# DDRSS0_PHY_CFG register map
Vendor: Texas Instruments
Peripheral module from a debugger description file (folder am65x).
Registers are 32-bit, access per field, reset 0x0 unless marked. A register's access mark holds for its fields unless they carry their own. Offsets are as the file gives them; lines under a group give offsets from that group; [hi:lo] are bit positions; {n}, {i} and the like mark numbered series; 'fields as' and 'values as' point back to an identical list; <NAME> marks a mode.

## DDRSS0_PHY_CFG (part 1 of 2)
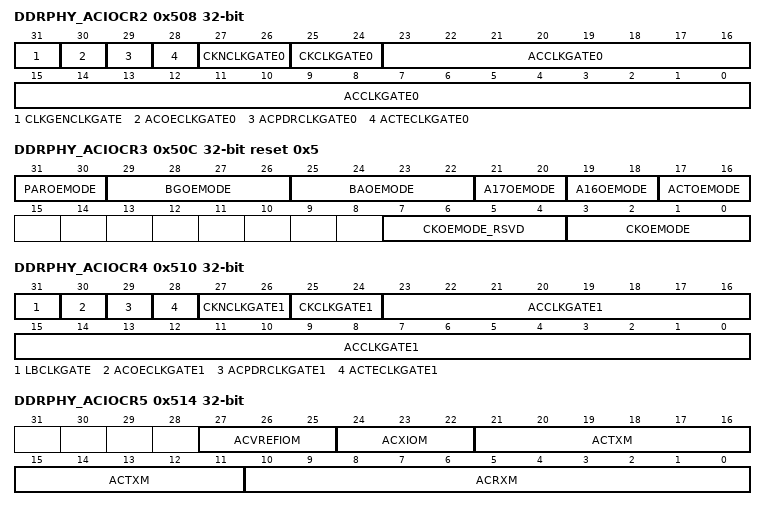
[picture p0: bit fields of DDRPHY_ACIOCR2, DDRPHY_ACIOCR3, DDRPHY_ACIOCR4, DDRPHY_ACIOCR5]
0x508 DDRPHY_ACIOCR2 rw — AC I/O Configuration Register 2
  [31] CLKGENCLKGATE — Clock gating for glue logic inside CLKGEN and glue logic inside CONTROL slice
  [30] ACOECLKGATE0 — Clock gating for Output Enable D slices [0]
  [29] ACPDRCLKGATE0 — Clock gating for Power Down Receiver D slices [0]
  [28] ACTECLKGATE0 — Clock gating for Termination Enable D slices [0]
  [27:26] CKNCLKGATE0 — Clock gating for CK# D slices[1:0]
  [25:24] CKCLKGATE0 — Clock gating for CK D slices[1:0]
  [23:0] ACCLKGATE0 — Clock gating for AC D slices[23:0]
0x50C DDRPHY_ACIOCR3 reset 0x5 — AC I/O Configuration Register 3
  [31:30] PAROEMODE rw — SDRAM Parity Output Enable (OE) Mode Selection
  [29:26] BGOEMODE rw — SDRAM Bank Group Output Enable (OE) Mode Selection
  [25:22] BAOEMODE rw — SDRAM Bank Address Output Enable (OE) Mode Selection
  [21:20] A17OEMODE rw — SDRAM A[17] Output Enable (OE) Mode Selection
  [19:18] A16OEMODE rw — SDRAM A[16] / RAS_n Output Enable (OE) Mode Selection
  [17:16] ACTOEMODE rw — SDRAM ACT_n Output Enable (OE) Mode Selection (DDR4 only)
  [7:4] CKOEMODE_RSVD ro — Reserved.Return zeros on reads.
  [3:0] CKOEMODE rw — SDRAM CK Output Enable (OE) Mode Selection.
0x510 DDRPHY_ACIOCR4 rw — AC I/O Configuration Register 4
  [31] LBCLKGATE — Clock gating for AC LB slices and loopback read valid slices
  [30] ACOECLKGATE1 — Clock gating for Output Enable D slices [1]
  [29] ACPDRCLKGATE1 — Clock gating for Power Down Receiver D slices [1]
  [28] ACTECLKGATE1 — Clock gating for Termination Enable D slices [1]
  [27:26] CKNCLKGATE1 — Clock gating for CK# D slices[3:2]
  [25:24] CKCLKGATE1 — Clock gating for CK D slices[3:2]
  [23:0] ACCLKGATE1 — Clock gating for AC D slices[47:24]
0x514 DDRPHY_ACIOCR5 — AC I/O Configuration Register 5
  [27:25] ACVREFIOM rw — IOM bits for PVREF and PVREFE cells in AC IO ring
  [24:22] ACXIOM rw — AC IO Mode
  [21:11] ACTXM rw — AC IO Transmitter Mode
  [10:0] ACRXM rw — AC IO Receiver Mode
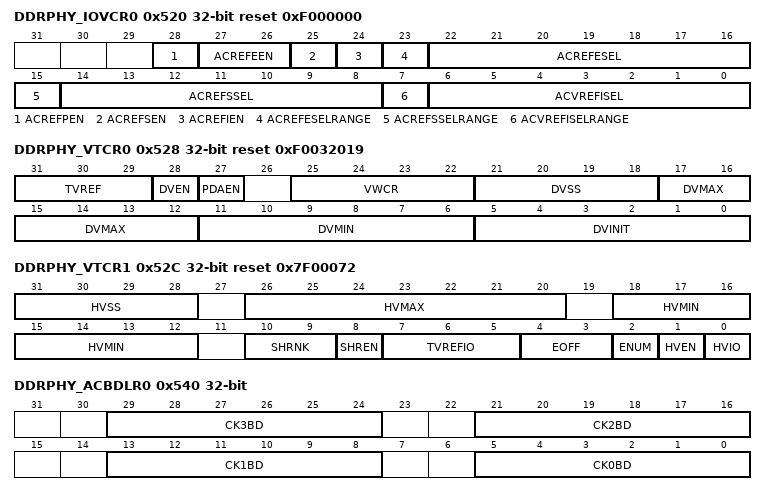
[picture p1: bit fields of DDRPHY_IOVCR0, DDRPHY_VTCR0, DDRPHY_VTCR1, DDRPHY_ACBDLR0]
0x520 DDRPHY_IOVCR0 reset 0xF000000 — IO VREF Control Register 0
  [28] ACREFPEN rw — Address/command lane VREF Pad Enable
  [27:26] ACREFEEN rw — Address/command lane Internal VREF Enable
  [25] ACREFSEN rw — Address/command lane Single-End VREF Enable
  [24] ACREFIEN rw — Address/command lane Internal VREF Enable
  [23] ACREFESELRANGE rw — External VREF generato REFSEL range select
  [22:16] ACREFESEL rw — Address/command lane External VREF Select
  [15] ACREFSSELRANGE rw — Single ended VREF generator REFSEL range select
  [14:8] ACREFSSEL rw — Address/command lane Single-End VREF Select
  [7] ACVREFISELRANGE rw — Internal VREF generator REFSEL ragne select
  [6:0] ACVREFISEL rw — REFSEL Control for internal AC IOs
0x528 DDRPHY_VTCR0 reset 0xF0032019 — VREF Training Control Register 0
  [31:29] TVREF rw — Number of ctl_clk required to meet (&gt; 150ns) timing requirements during DRAM DQ VREF training
  [28] DVEN rw — DRAM DQ VREF training Enable
  [27] PDAEN rw — Per Device Addressability Enable
  [25:22] VWCR rw — VREF Word Count
  [21:18] DVSS rw — DRAM DQ VREF step size used during DRAM VREF training
  [17:12] DVMAX rw — Maximum VREF limit value used during DRAM VREF training
  [11:6] DVMIN rw — Minimum VREF limit value used during DRAM VREF training
  [5:0] DVINIT rw — Initial DRAM DQ VREF value used during DRAM VREF training
0x52C DDRPHY_VTCR1 reset 0x7F00072 — VREF Training Control Register 1
  [31:28] HVSS rw — Host VREF step size used during VREF training.The register value of N indicates step size of (N+1)
  [26:20] HVMAX rw — Maximum VREF limit value used during DRAM VREF training.
  [18:12] HVMIN rw — Minimum VREF limit value used during DRAM VREF training.
  [10:9] SHRNK rw — Static Host Vref Rank Value
  [8] SHREN rw — Static Host Vref Rank Enable
  [7:5] TVREFIO rw — Number of ctl_clk required to meet (&gt; 200ns) VREF Settling timing requirements during Host IO VREF training
  [4:3] EOFF rw — Eye LCDL Offset value for VREF training
  [2] ENUM rw — Number of LCDL Eye points for which VREF training is repeated
  [1] HVEN rw — HOST (IO) internal VREF training Enable
  [0] HVIO rw — Host IO Type Control
0x540 DDRPHY_ACBDLR0 — AC Bit Delay Line Register 0
  [8n+5:8n] CK{n}BD rw (n=0..3) — CK{n} Bit Delay
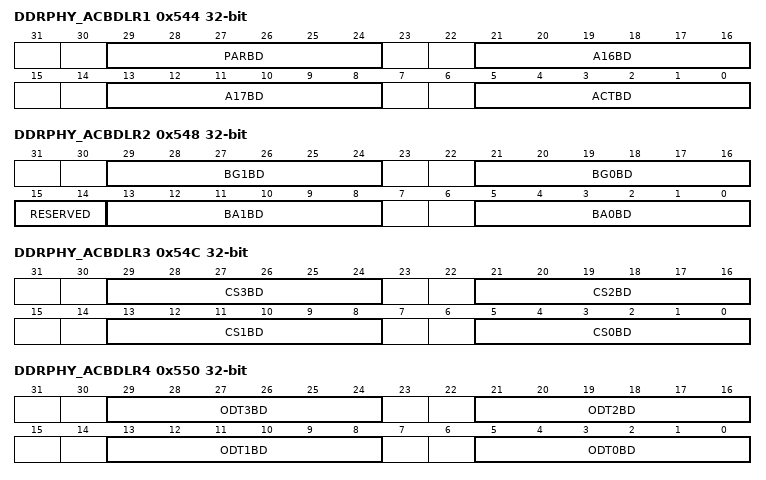
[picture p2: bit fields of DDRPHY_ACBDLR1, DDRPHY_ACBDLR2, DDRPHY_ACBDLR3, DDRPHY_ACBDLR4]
0x544 DDRPHY_ACBDLR1 — AC Bit Delay Line Register 1
  [29:24] PARBD rw — Delay select for the BDL on Parity.
  [21:16] A16BD rw — Delay select for the BDL on Address A[16].In DDR3 mode this pin is connected to WE.
  [13:8] A17BD rw — Delay select for the BDL on Address A[17].When not in DDR4 modemode this pin is connected to CAS.
  [5:0] ACTBD rw — Delay select for the BDL on ACTN.
0x548 DDRPHY_ACBDLR2 — AC Bit Delay Line Register 2
  [29:24] BG1BD rw — Delay select for the BDL on BG[1].
  [21:16] BG0BD rw — Delay select for the BDL on BG[0].
  [15:14] RESERVED ro — Reser.ved Return zeroes on reads.
  [13:8] BA1BD rw — Delay select for the BDL on BA[1].
  [5:0] BA0BD rw — Delay select for the BDL on BA[0].
0x54C DDRPHY_ACBDLR3 — AC Bit Delay Line Register 3
  [29:24] CS3BD ro — Delay select for the BDL on CS[3].
  [21:16] CS2BD ro — Delay select for the BDL on CS[2].
  [13:8] CS1BD rw — Delay select for the BDL on CS[1].
  [5:0] CS0BD rw — Delay select for the BDL on CS[0].
0x550 DDRPHY_ACBDLR4 — AC Bit Delay Line Register 4
  [29:24] ODT3BD ro — Delay select for the BDL on ODT[3].
  [21:16] ODT2BD ro — Delay select for the BDL on ODT[2].
  [13:8] ODT1BD rw — Delay select for the BDL on ODT[1].
  [5:0] ODT0BD rw — Delay select for the BDL on ODT[0].
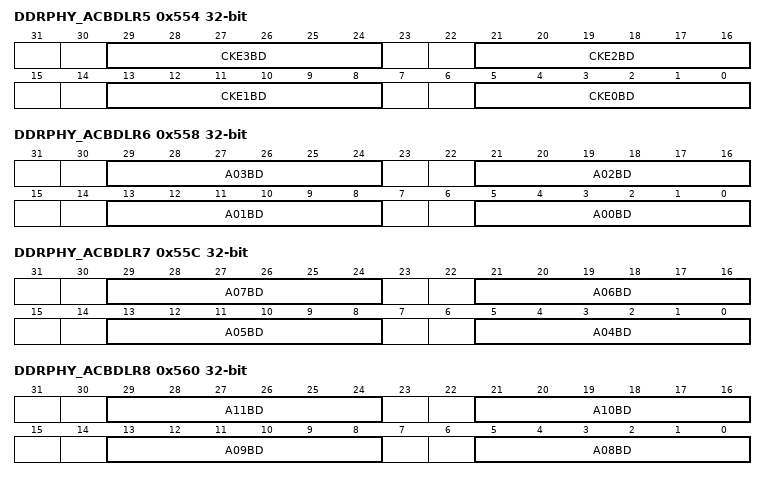
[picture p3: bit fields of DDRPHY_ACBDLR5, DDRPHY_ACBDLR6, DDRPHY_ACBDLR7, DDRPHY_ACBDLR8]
0x554 DDRPHY_ACBDLR5 — AC Bit Delay Line Register 5
  [29:24] CKE3BD ro — Delay select for the BDL on CKE[3].
  [21:16] CKE2BD ro — Delay select for the BDL on CKE[2].
  [13:8] CKE1BD rw — Delay select for the BDL on CKE[1].
  [5:0] CKE0BD rw — Delay select for the BDL on CKE[0].
0x558 DDRPHY_ACBDLR6 — AC Bit Delay Line Register 6
  [8n+5:8n] A{n:02}BD rw (n=0..3) — Delay select for the BDL on Address A[{n}].
0x55C DDRPHY_ACBDLR7 — AC Bit Delay Line Register 7
  [8n-27:8n-32] A{n:02}BD rw (n=4..7) — Delay select for the BDL on Address A[{n}].
0x560 DDRPHY_ACBDLR8 — AC Bit Delay Line Register 8
  [8n-59:8n-64] A{n:02}BD rw (n=8..11) — Delay select for the BDL on Address A[{n}].
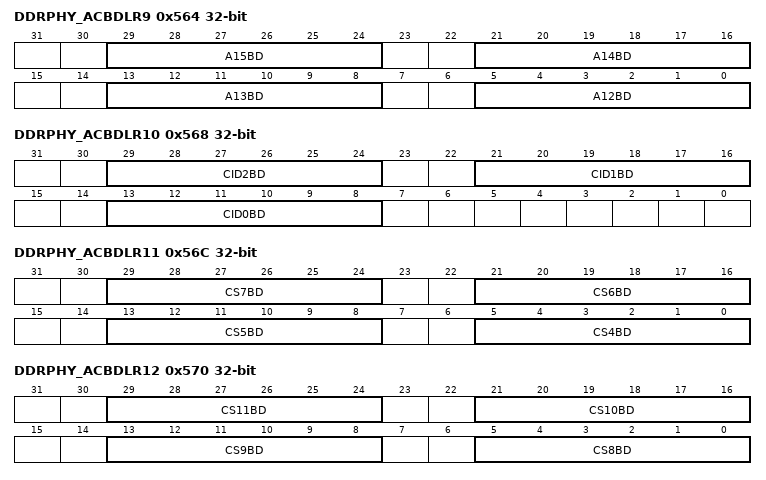
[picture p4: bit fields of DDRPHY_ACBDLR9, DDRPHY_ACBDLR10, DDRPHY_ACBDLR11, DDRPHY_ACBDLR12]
0x564 DDRPHY_ACBDLR9 — AC Bit Delay Line Register 9
  [8n-91:8n-96] A{n}BD rw (n=12..15) — Delay select for the BDL on Address A[{n}].
0x568 DDRPHY_ACBDLR10 — AC Bit Delay Line Register 10
  [29:24] CID2BD ro — Delay select for the BDL on Chip ID CID[2]
  [21:16] CID1BD ro — Delay select for the BDL on Chip ID CID[1]
  [13:8] CID0BD rw — Delay select for the BDL on Chip ID CID[0]
0x56C DDRPHY_ACBDLR11 ro — AC Bit Delay Line Register 11
  [8n-27:8n-32] CS{n}BD (n=4..7) — Delay select for the BDL on CS[{n}]
0x570 DDRPHY_ACBDLR12 ro — AC Bit Delay Line Register 12
  [8n-59:8n-64] CS{n}BD (n=8..11) — Delay select for the BDL on CS[{n}]
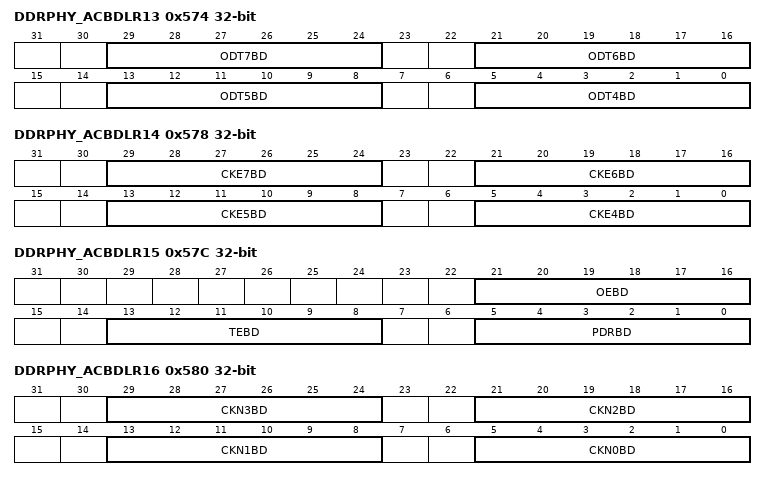
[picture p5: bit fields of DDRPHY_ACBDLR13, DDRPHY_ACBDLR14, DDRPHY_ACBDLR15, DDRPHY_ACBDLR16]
0x574 DDRPHY_ACBDLR13 ro — AC Bit Delay Line Register 13
  [8n-27:8n-32] ODT{n}BD (n=4..7) — Delay select for the BDL on ODT[{n}]
0x578 DDRPHY_ACBDLR14 ro — AC Bit Delay Line Register 14
  [8n-27:8n-32] CKE{n}BD (n=4..7) — Delay select for the BDL on CKE[{n}]
0x57C DDRPHY_ACBDLR15 — AC Bit Delay Line Register 15
  [21:16] OEBD rw — Delay select for the BDL on OE
  [13:8] TEBD rw — Delay select for the BDL on TE
  [5:0] PDRBD rw — Delay select for the BDL on PDR
0x580 DDRPHY_ACBDLR16 — AC Bit Delay Line Register 16
  [8n+5:8n] CKN{n}BD rw (n=0..3) — Delay select for the BDL on CKN[{n}]
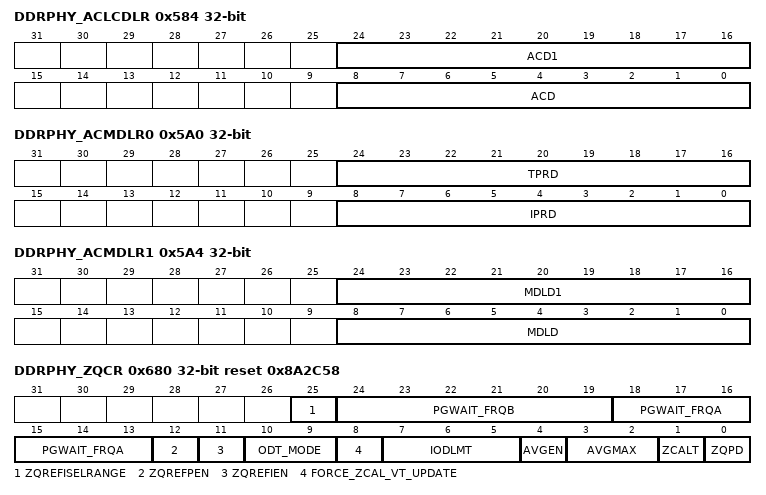
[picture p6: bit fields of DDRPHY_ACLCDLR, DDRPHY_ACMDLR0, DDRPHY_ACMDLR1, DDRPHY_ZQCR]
0x584 DDRPHY_ACLCDLR — AC Local Calibrated Delay Line Register
  [24:16] ACD1 rw — Address/Command Delay for AC Macro 1
  [8:0] ACD rw — Address/Command Delay for AC Macro 0
0x5A0 DDRPHY_ACMDLR0 — AC Master Delay Line Register 0
  [24:16] TPRD rw — Target Period
  [8:0] IPRD rw — Initial Period
0x5A4 DDRPHY_ACMDLR1 — AC Master Delay Line Register 1
  [24:16] MDLD1 rw — MDL Delay for AC Macro 1
  [8:0] MDLD rw — MDL Delay for AC Macro 0
0x680 DDRPHY_ZQCR reset 0x8A2C58 — ZQ Impedance Control Register
  [25] ZQREFISELRANGE rw — ZQ VREF Range
  [24:19] PGWAIT_FRQB rw — Programmable Wait for Frequency B
  [18:13] PGWAIT_FRQA rw — Programmable Wait for Frequency A
  [12] ZQREFPEN rw — ZQ VREF Pad Enable
  [11] ZQREFIEN rw — ZQ Internal VREF Enable
  [10:9] ODT_MODE rw — Choice of termination mode
  [8] FORCE_ZCAL_VT_UPDATE rw
  [7:5] IODLMT rw — IO VT Drift Limit
  [4] AVGEN rw — Averaging algorithm enable, if set, enables averaging algorithm
  [3:2] AVGMAX rw — Maximum number of averaging rounds to be used by averaging algorithm
  [1] ZCALT rw — ZQ Calibration Type
  [0] ZQPD rw — ZQ Power Down
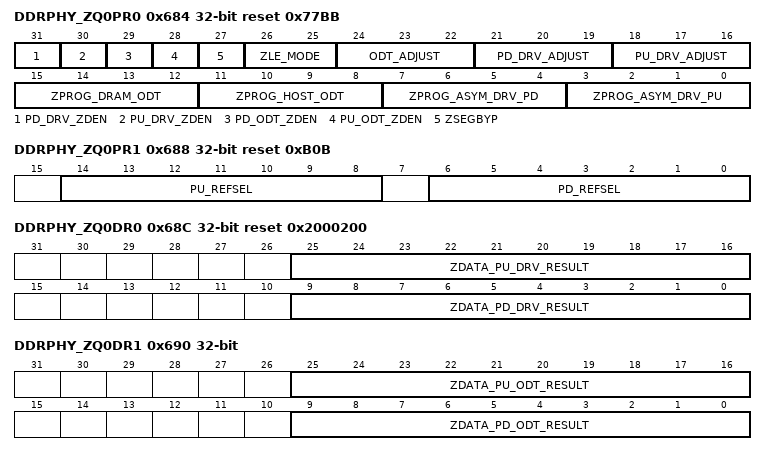
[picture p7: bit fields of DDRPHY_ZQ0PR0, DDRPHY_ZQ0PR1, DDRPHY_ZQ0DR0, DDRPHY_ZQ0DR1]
0x684 DDRPHY_ZQ0PR0 rw reset 0x77BB — ZQ n Impedance Control Program Register 0
  [31] PD_DRV_ZDEN — Pull-down drive strength ZCTRL over-ride enable
  [30] PU_DRV_ZDEN — Pull-up drive strength ZCTRL over-ride enable
  [29] PD_ODT_ZDEN — Pull-down termination ZCTRL over-ride enable
  [28] PU_ODT_ZDEN — Pull-up termination ZCTRL over-ride enable
  [27] ZSEGBYP — Calibration segment bypass
  [26:25] ZLE_MODE — VREF latch mode controls the mode in which the ZLE pin of the PVREF cell is driven by the PUB
  [24:22] ODT_ADJUST — Termination adjustment
  [21:19] PD_DRV_ADJUST — Pulldown drive strength adjustment
  [18:16] PU_DRV_ADJUST — Pullup drive strength adjustment
  [15:12] ZPROG_DRAM_ODT — DRAM Impedance Divide Ratio
  [11:8] ZPROG_HOST_ODT — HOST Impedance Divide Ratio
  [7:4] ZPROG_ASYM_DRV_PD — Impedance Divide Ratio (pulldown drive calibration during asymmetric drive strength calibration)
  [3:0] ZPROG_ASYM_DRV_PU — Impedance Divide Ratio (pullup drive calibration during asymmetric drive strength calibration)
0x688 DDRPHY_ZQ0PR1 reset 0xB0B — ZQ n Impedance Control Program Register 1
  [14:8] PU_REFSEL rw — Pull-up REFSEL for PZCTRL cell
  [6:0] PD_REFSEL rw — Pull-down REFSEL for PZCTRL cell
0x68C DDRPHY_ZQ0DR0 ro reset 0x2000200 — ZQ n Impedance Control Data Register 0
  [25:16] ZDATA_PU_DRV_RESULT — Pull-up drive strength calibration code result
  [9:0] ZDATA_PD_DRV_RESULT — Pull-down drive strength calibration code result
0x690 DDRPHY_ZQ0DR1 ro — ZQ n Impedance Control Data Register 1
  [25:16] ZDATA_PU_ODT_RESULT — Pull-up termination calibration code result
  [9:0] ZDATA_PD_ODT_RESULT — Pull-down termination calibration code result
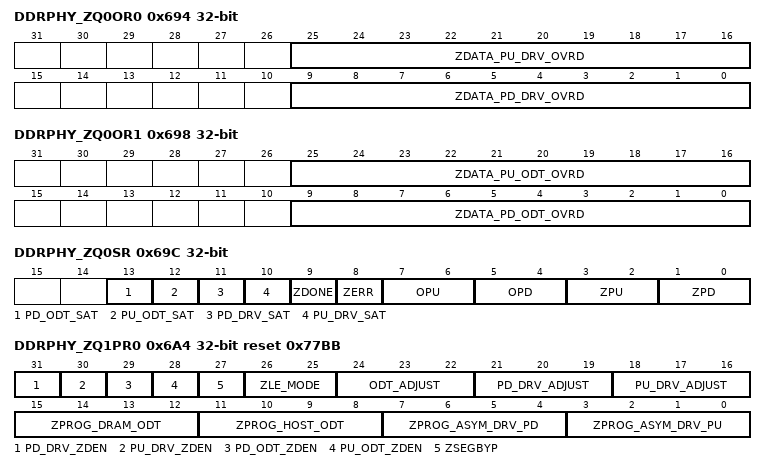
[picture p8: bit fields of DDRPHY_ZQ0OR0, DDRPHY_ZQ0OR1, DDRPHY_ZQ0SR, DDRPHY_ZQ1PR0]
0x694 DDRPHY_ZQ0OR0 — ZQ n Impedance Control Override Data Register 0
  [25:16] ZDATA_PU_DRV_OVRD rw — Override value for the pull-up output impedance
  [9:0] ZDATA_PD_DRV_OVRD rw — Override value for the pull-down output impedance
0x698 DDRPHY_ZQ0OR1 — ZQ n Impedance Control Override Data Register 1
  [25:16] ZDATA_PU_ODT_OVRD rw — Override value for the pull-up termination
  [9:0] ZDATA_PD_ODT_OVRD rw — Override value for the pull-down termination
0x69C DDRPHY_ZQ0SR ro — ZQ n Impedance Control Status Register
  [13] PD_ODT_SAT — Pulldown drive strength code saturated due to termination strength adjustment setting in ZQnPR register
  [12] PU_ODT_SAT — Pullup drive strength code saturated due to termination strength adjustment setting in ZQnPR register
  [11] PD_DRV_SAT — Pulldown drive strength code saturated due to drive strength adjustment setting in ZQnPR register
  [10] PU_DRV_SAT — Pullup drive strength code saturated due to drive strength adjustment setting in ZQnPR register
  [9] ZDONE — Impedance Calibration Done
  [8] ZERR — Impedance Calibration Error
  [7:6] OPU — On-die termination (ODT) pull-up calibration status
  [5:4] OPD — On-die termination (ODT) pull-down calibration status
  [3:2] ZPU — Output impedance pull-up calibration status
  [1:0] ZPD — Output impedance pull-down calibration status
0x6A4 DDRPHY_ZQ1PR0 rw reset 0x77BB — ZQ n Impedance Control Program Register 0
  fields as DDRPHY_ZQ0PR0
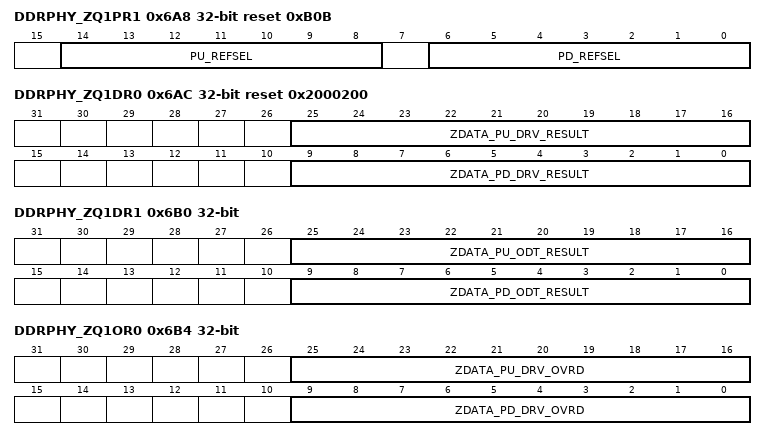
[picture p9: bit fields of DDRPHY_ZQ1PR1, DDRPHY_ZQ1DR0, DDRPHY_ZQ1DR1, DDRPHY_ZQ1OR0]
0x6A8 DDRPHY_ZQ1PR1 reset 0xB0B — ZQ n Impedance Control Program Register 1
  fields as DDRPHY_ZQ0PR1
0x6AC DDRPHY_ZQ1DR0 ro reset 0x2000200 — ZQ n Impedance Control Data Register 0
  fields as DDRPHY_ZQ0DR0
0x6B0 DDRPHY_ZQ1DR1 ro — ZQ n Impedance Control Data Register 1
  fields as DDRPHY_ZQ0DR1
0x6B4 DDRPHY_ZQ1OR0 — ZQ n Impedance Control Override Data Register 0
  fields as DDRPHY_ZQ0OR0
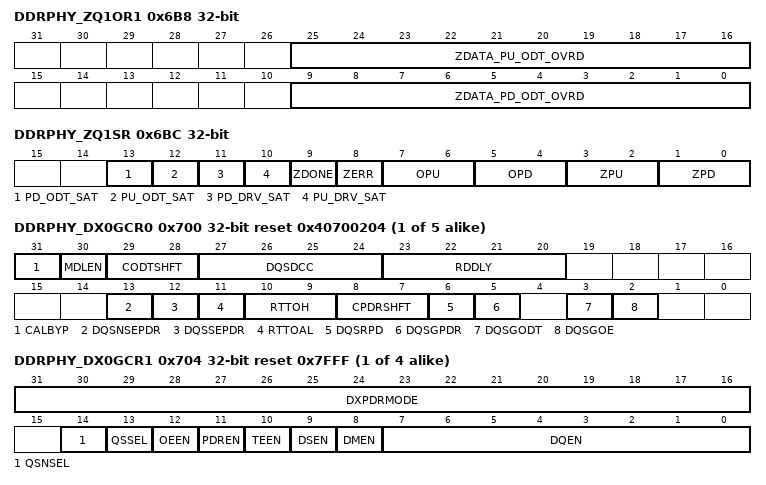
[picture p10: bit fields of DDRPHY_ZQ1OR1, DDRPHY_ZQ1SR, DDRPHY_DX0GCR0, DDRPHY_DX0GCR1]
0x6B8 DDRPHY_ZQ1OR1 — ZQ n Impedance Control Override Data Register 1
  fields as DDRPHY_ZQ0OR1
0x6BC DDRPHY_ZQ1SR ro — ZQ n Impedance Control Status Register
  fields as DDRPHY_ZQ0SR
{0x700+0x100*i} DDRPHY_DX{i}GCR0 reset 0x40700204 (i=0..4) — DATX8 n General Configuration Register 0
  [31] CALBYP rw — Calibration Bypass
  [30] MDLEN rw — Master Delay Line Enable
  [29:28] CODTSHFT rw — Configurable ODT(TE) Phase Shift
  [27:24] DQSDCC rw — DQS Duty Cycle Correction
  [23:20] RDDLY rw — Number of Cycles ( in terms of ctl_clk) to generate ctl_dx_get_static_rd input for the respective bypte lane of the PHY
  [13] DQSNSEPDR rw — DQSNSE Power Down Receiver
  [12] DQSSEPDR rw — DQSSE Power Down Receiver
  [11] RTTOAL rw — RTT On Additive Latency
  [10:9] RTTOH rw — RTT Output Hold
  [8:7] CPDRSHFT rw — Configurable PDR Phase Shift
  [6] DQSRPD rw — DQSR Power Down
  [5] DQSGPDR rw — DQSG Power Down Receiver
  [3] DQSGODT rw — DQSG On-Die Termination
  [2] DQSGOE rw — DQSG Output Enable
{0x704+0x100*i} DDRPHY_DX{i}GCR1 reset 0x7FFF (i=0..3) — DATX8 n General Configuration Register 1
  [31:16] DXPDRMODE rw — Enables the PDR mode for DQ[7:0]
  [14] QSNSEL rw — Select the delayed or non-delayed read data strobe #
  [13] QSSEL rw — Select the delayed or non-delayed read data strobe
  [12] OEEN rw — Enables Read Data Strobe in a byte lane
  [11] PDREN rw — Enables PDR in a byte lane
  [10] TEEN rw — Enables ODT/TE in a byte lane
  [9] DSEN rw — Enables Write Data strobe in a byte lane
  [8] DMEN rw — Enables DM pin in a byte lane
  [7:0] DQEN rw — Enables DQ corresponding to each bit in a byte
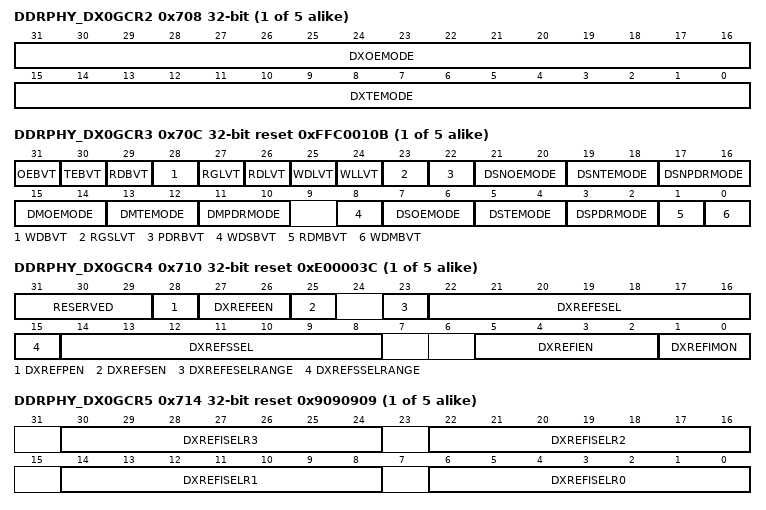
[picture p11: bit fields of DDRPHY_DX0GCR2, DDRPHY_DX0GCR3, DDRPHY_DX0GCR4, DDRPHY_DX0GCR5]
{0x708+0x100*i} DDRPHY_DX{i}GCR2 rw (i=0..4) — DATX8 n General Configuration Register 2
  [31:16] DXOEMODE — Enables the OE mode values for DQ[7:0]
  [15:0] DXTEMODE — Enables the TE (ODT) mode values for DQ[7:0]
{0x70C+0x100*i} DDRPHY_DX{i}GCR3 reset 0xFFC0010B (i=0..4) — DATX8 n General Configuration Register 3
  [31] OEBVT rw — Output Enable BDL VT Compensation
  [30] TEBVT rw — Termination Enable BDL VT Compensation
  [29] RDBVT rw — Read Data BDL VT Compensation
  [28] WDBVT rw — Write Data BDL VT Compensation
  [27] RGLVT rw — Read DQS Gating LCDL Delay VT Compensation
  [26] RDLVT rw — Read DQS LCDL Delay VT Compensation
  [25] WDLVT rw — Write DQ LCDL Delay VT Compensation
  [24] WLLVT rw — Write Leveling LCDL Delay VT Compensation
  [23] RGSLVT rw — Read DQS Gating Status LCDL Delay VT Compensation
  [22] PDRBVT rw — Power Down Receiver BDL VT Compensation
  [21:20] DSNOEMODE rw — Enables the OE mode for DQs
  [19:18] DSNTEMODE rw — Enables the TE mode for DQS
  [17:16] DSNPDRMODE rw — Enables the PDR mode for DQS
  [15:14] DMOEMODE rw — Enables the OE mode values for DM.
  [13:12] DMTEMODE rw — Enables the TE mode values for DM.
  [11:10] DMPDRMODE rw — Enables the PDR mode values for DM.
  [8] WDSBVT rw — Write Data Strobe BDL VT Compensation
  [7:6] DSOEMODE rw — Enables the OE mode values for DQS.
  [5:4] DSTEMODE rw — Enables the TE mode values for DQS.
  [3:2] DSPDRMODE rw — Enables the PDR mode values for DQS.
  [1] RDMBVT rw — Read Data Mask BDL VT Compensation
  [0] WDMBVT rw — Write Data Mask BDL VT Compensation
{0x710+0x100*i} DDRPHY_DX{i}GCR4 reset 0xE00003C (i=0..4) — DATX8 n General Configuration Register 4
  [31:29] RESERVED ro — Byte lane VREF IOM (Used only by D4MU IOs)
  [28] DXREFPEN rw — Byte Lane VREF Pad Enable
  [27:26] DXREFEEN rw — Byte Lane Internal VREF Enable
  [25] DXREFSEN rw — Byte Lane Single-End VREF Enable
  [23] DXREFESELRANGE rw — External VREF generator REFSEL range select
  [22:16] DXREFESEL rw — Byte Lane External VREF Select
  [15] DXREFSSELRANGE rw — Single ended VREF generator REFSEL range select
  [14:8] DXREFSSEL rw — Byte Lane Single-End VREF Select
  [5:2] DXREFIEN rw — VREF Enable control for DQ IO (Single Ended) buffers of a byte lane.
  [1:0] DXREFIMON rw — VRMON control for DQ IO (Single Ended) buffers of a byte lane.
{0x714+0x100*i} DDRPHY_DX{i}GCR5 reset 0x9090909 (i=0..4) — DATX8 n General Configuration Register 5
  [8n+6:8n] DXREFISELR{n} rw (n=0..3) — Byte Lane internal VREF Select for Rank {n}
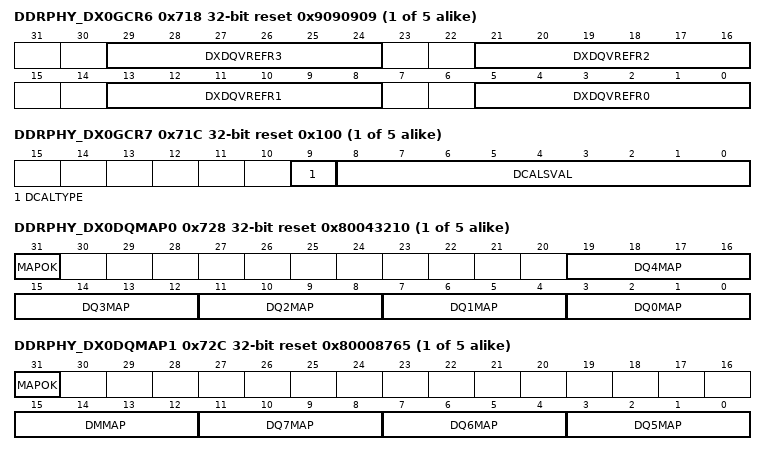
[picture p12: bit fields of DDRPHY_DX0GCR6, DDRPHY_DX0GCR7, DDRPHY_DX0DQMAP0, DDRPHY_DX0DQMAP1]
{0x718+0x100*i} DDRPHY_DX{i}GCR6 reset 0x9090909 (i=0..4) — DATX8 n General Configuration Register 6
  [8n+5:8n] DXDQVREFR{n} rw (n=0..3) — DRAM DQ VREF Select for Rank{n}
{0x71C+0x100*i} DDRPHY_DX{i}GCR7 reset 0x100 (i=0..4) — DATX8 n General Configuration Register 7
  [9] DCALTYPE rw — DDL Calibration Type
  [8:0] DCALSVAL rw — DDL Calibration Starting Value
{0x720+0x100*i} DDRPHY_DX{i}GCR8 ro (i=0..4) — DATX8 n General Configuration Register 8
{0x724+0x100*i} DDRPHY_DX{i}GCR9 ro (i=0..4) — DATX8 n General Configuration Register 9
{0x728+0x100*i} DDRPHY_DX{i}DQMAP0 reset 0x80043210 (i=0..4) — DATX8 n DQ/DM Mapping Register 0
  [31] MAPOK ro — Checksum bit
  [4n+3:4n] DQ{n}MAP rw (n=0..4) — DQ bit {n} DATX8 slice mapping index
{0x72C+0x100*i} DDRPHY_DX{i}DQMAP1 reset 0x80008765 (i=0..4) — DATX8 n DQ/DM Mapping Register 1
  [31] MAPOK ro — Checksum bit
  [15:12] DMMAP rw — DM bit DATX8 slice mapping index
  [11:8] DQ7MAP rw — DQ bit 7 DATX8 slice mapping index
  [7:4] DQ6MAP rw — DQ bit 6 DATX8 slice mapping index
  [3:0] DQ5MAP rw — DQ bit 5 DATX8 slice mapping index
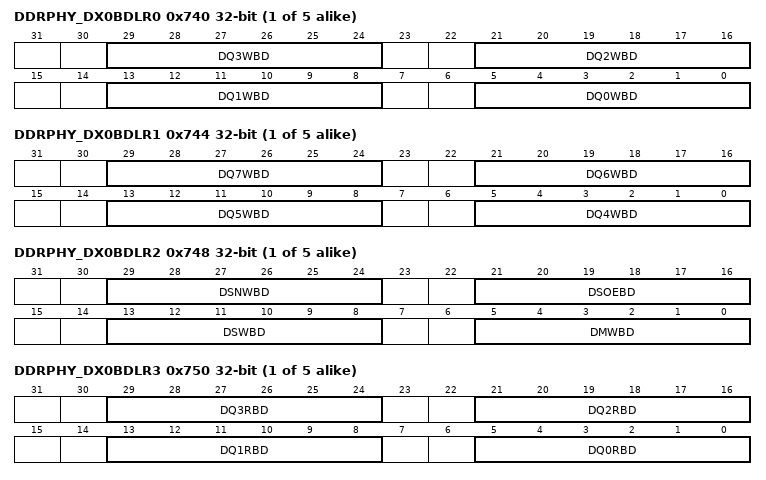
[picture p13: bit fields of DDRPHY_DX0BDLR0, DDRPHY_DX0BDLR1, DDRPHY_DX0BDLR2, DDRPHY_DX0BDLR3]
{0x740+0x100*i} DDRPHY_DX{i}BDLR0 (i=0..4) — DATX8 n Bit Delay Line Register 0
  [8n+5:8n] DQ{n}WBD rw (n=0..3) — DQ{n} Write Bit Delay
{0x744+0x100*i} DDRPHY_DX{i}BDLR1 (i=0..4) — DATX8 n Bit Delay Line Register 1
  [8n-27:8n-32] DQ{n}WBD rw (n=4..7) — DQ{n} Write Bit Delay
{0x748+0x100*i} DDRPHY_DX{i}BDLR2 (i=0..4) — DATX8 n Bit Delay Line Register 2
  [29:24] DSNWBD rw — DQSN Write Bit Delay
  [21:16] DSOEBD rw — DQS/DM/DQ Output Enable Bit Delay
  [13:8] DSWBD rw — DQS Write Bit Delay
  [5:0] DMWBD rw — DM Write Bit Delay
{0x750+0x100*i} DDRPHY_DX{i}BDLR3 (i=0..4) — DATX8 n Bit Delay Line Register 3
  [8n+5:8n] DQ{n}RBD rw (n=0..3) — DQ{n} Read Bit Delay
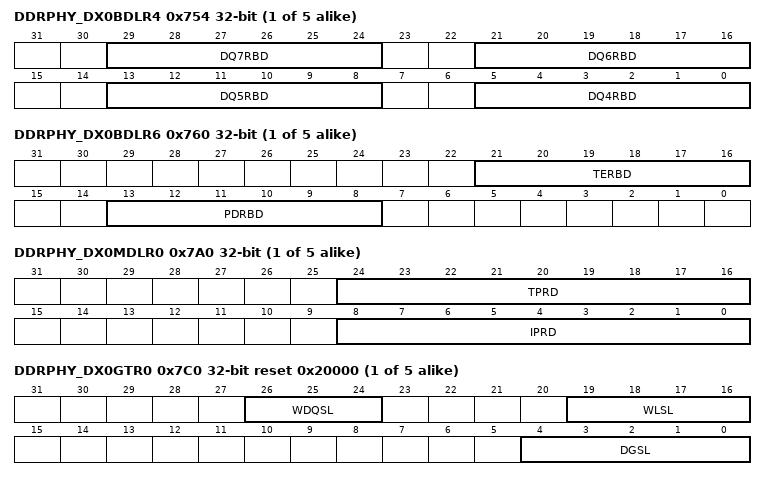
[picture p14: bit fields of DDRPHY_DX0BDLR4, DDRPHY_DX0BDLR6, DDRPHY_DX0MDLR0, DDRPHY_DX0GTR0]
{0x754+0x100*i} DDRPHY_DX{i}BDLR4 (i=0..4) — DATX8 n Bit Delay Line Register 4
  [8n-27:8n-32] DQ{n}RBD rw (n=4..7) — DQ{n} Read Bit Delay
{0x758+0x100*i} DDRPHY_DX{i}BDLR5 (i=0..4) — DATX8 n Bit Delay Line Register 5
  [5:0] DMRBD rw — DM Read Bit Delay
{0x760+0x100*i} DDRPHY_DX{i}BDLR6 (i=0..4) — DATX8 n Bit Delay Line Register 6
  [21:16] TERBD rw — Termination Enable Bit Delay
  [13:8] PDRBD rw — Power down receiver Bit Delay
{0x764+0x100*i} DDRPHY_DX{i}BDLR7 ro (i=0..4) — DATX8 n Bit Delay Line Register 7
{0x768+0x100*i} DDRPHY_DX{i}BDLR8 ro (i=0..4) — DATX8 n Bit Delay Line Register 8
{0x76C+0x100*i} DDRPHY_DX{i}BDLR9 ro (i=0..4) — DATX8 n Bit Delay Line Register 9
{0x780+0x100*i} DDRPHY_DX{i}LCDLR0 (i=0..4) — DATX8 n Local Calibrated Delay Line Register 0
  [8:0] WLD rw — Write Leveling Delay
{0x784+0x100*i} DDRPHY_DX{i}LCDLR1 (i=0..4) — DATX8 n Local Calibrated Delay Line Register 1
  [8:0] WDQD rw — Write Data Delay
{0x788+0x100*i} DDRPHY_DX{i}LCDLR2 (i=0..4) — DATX8 n Local Calibrated Delay Line Register 2
  [8:0] DQSGD rw — Read DQS Gating Delay
{0x78C+0x100*i} DDRPHY_DX{i}LCDLR3 (i=0..4) — DATX8 n Local Calibrated Delay Line Register 3
  [8:0] RDQSD rw — Read DQS Delay
{0x790+0x100*i} DDRPHY_DX{i}LCDLR4 (i=0..4) — DATX8 n Local Calibrated Delay Line Register 4
  [8:0] RDQSND rw — Read DQSN Delay
{0x794+0x100*i} DDRPHY_DX{i}LCDLR5 (i=0..4) — DATX8 n Local Calibrated Delay Line Register 5
  [8:0] DQSGSD rw — DQS Gating Status Delay
{0x7A0+0x100*i} DDRPHY_DX{i}MDLR0 (i=0..4) — DATX8 n Master Delay Line Register 0
  [24:16] TPRD rw — Target Period
  [8:0] IPRD rw — Initial Period
{0x7A4+0x100*i} DDRPHY_DX{i}MDLR1 (i=0..4) — DATX8 n Master Delay Line Register 1
  [8:0] MDLD rw — MDL Delay
{0x7C0+0x100*i} DDRPHY_DX{i}GTR0 reset 0x20000 (i=0..4) — DATX8 n General Timing Register 0
  [26:24] WDQSL rw — DQ Write Path Latency Pipeline
  [19:16] WLSL rw — Write Leveling System Latency
  [4:0] DGSL rw — DQS Gating System Latency
{0x7D0+0x100*i} DDRPHY_DX{i}RSR0 ro (i=0..4) — DATX8 n Rank Status Register 0
  [15:0] QSGERR — DQS Gate Training Error
{0x7D4+0x100*i} DDRPHY_DX{i}RSR1 ro (i=0..4) — DATX8 n Rank Status Register 1
  [15:0] RDLVLERR — Read Leveling Error
{0x7D8+0x100*i} DDRPHY_DX{i}RSR2 ro (i=0..4) — DATX8 n Rank Status Register 2
  [15:0] WLAWN — Write Latency Adjustment (DQS off on some DQ lines) Warning
{0x7DC+0x100*i} DDRPHY_DX{i}RSR3 ro (i=0..4) — DATX8 n Rank Status Register 3
  [15:0] WLAERR — Write Leveling Adjustment Error
{0x7E0+0x100*i} DDRPHY_DX{i}GSR0 ro (i=0..4) — DATX8 n General Status Register 0
  [30] WLDQ — Write Leveling DQ Status
  [25:17] GDQSPRD — Read DQS gating Period
  [16] DPLOCK — DATX8 PLL Lock
  [15:7] WLPRD — Write Leveling Period
  [6] WLERR — Write Leveling Error
  [5] WLDONE — Write Leveling Done
  [4] WLCAL — Write Leveling Calibration
  [3] GDQSCAL — Read DQS gating Calibration
  [2] RDQSNCAL — Read DQS# Calibration
  [1] RDQSCAL — Read DQS Calibration
  [0] WDQCAL — Write DQ Calibration
{0x7E4+0x100*i} DDRPHY_DX{i}GSR1 ro (i=0..4) — DATX8 n General Status Register 1
  [24:1] DLTCODE — Delay Line Test Code
  [0] DLTDONE — Delay Line Test Done
{0x7E8+0x100*i} DDRPHY_DX{i}GSR2 ro (i=0..4) — DATX8 n General Status Register 2
  [31:23] GSDQSPRD — Read DQS gating Status Period
  [22] GSDQSCAL — Read DQS Gating Status Calibration
  [20] SRDERR — Static Read Error
  [19:12] DQS2DQERR — Write DQS2DQ Training Error
  [11:8] ESTAT — Error Status
  [7] WEWN — Write Eye Centering Warning
  [6] WEERR — Write Eye Centering Error
  [5] REWN — Read Eye Centering Warning
  [4] REERR — Read Eye Centering Error
  [3] WDWN — Write Bit Deskew Warning
  [2] WDERR — Write Bit Deskew Error
  [1] RDWN — Read Bit Deskew Warning
  [0] RDERR — Read Bit Deskew Error
{0x7EC+0x100*i} DDRPHY_DX{i}GSR3 ro (i=0..4) — DATX8 n General Status Register 3
  [26:24] ESTAT — VREF Training Error Status Code
  [23:20] DVWRN — DRAM VREF Training Warning
  [19:16] DVERR — DRAM VREF Training Error
  [15:12] HVWRN — Host VREF Training Warning
  [11:8] HVERR — Host VREF Training Error
  [1:0] SRDPC — Static Read Delay Pass Count
{0x7F0+0x100*i} DDRPHY_DX{i}GSR4 ro (i=0..4) — DATX8 n General Status Register 4
{0x7F4+0x100*i} DDRPHY_DX{i}GSR5 ro (i=0..4) — DATX8 n General Status Register 5
{0x7F8+0x100*i} DDRPHY_DX{i}GSR6 ro (i=0..4) — DATX8 n General Status Register 6
  [31:24] DBDQ — Capture DB DQ[7:0], bits [31:28] is for DQ[[7:4] for upper nibble, bits [27:24] is for DQ[3:0] for lower nibble.
0xB04 DDRPHY_DX4GCR1 reset 0x7F7F — DATX8 n General Configuration Register 1
  fields as DDRPHY_DX0GCR1
{0x1434+0x40*i} DDRPHY_DX4SL{i}IOCR ro (i=0..8) — DATX4 Slice 0-1 I/O Configuration Register
0x1440 DDRPHY_DX8SL1OSC access not given reset 0x19FFE — DATX8 0-1 Oscillator, Delay Line Test, PHY FIFO and High Speed Reset, Loopback, and Gated Clock Control Register
  [29:28] GATEDXRDCLK rw — Enable Clock Gating for DX ddr_clk
  [27:26] GATEDXDDRCLK rw — Enable Clock Gating for DX ctl_rd_clk
  [25:24] GATEDXCTLCLK rw — Enable Clock Gating for DX ctl_clk
  [23:22] CLKLEVEL rw — Selects the level to which clocks will be stalled when clock gating is enabled.
  [21] LBMODE rw — Loopback Mode
  [20] LBGSDQS — Load GSDQS LCDL with 2x the calibrated GSDQSPRD value (access RW1C)
  [19:18] LBGDQS rw — Loopback DQS Gating
  [17] LBDQSS rw — Loopback DQS Shift
  [16] PHYHRST rw — PHY High-Speed Reset
  [15] PHYFRST rw — PHY FIFO Reset
  [14] DLTST rw — Delay Line Test Start
  [13] DLTMODE rw — Delay Line Test Mode
  [10:9] OSCWDDL rw — Oscillator Mode Write-Data Delay Line Select
  [6:5] OSCWDL rw — Oscillator Mode Write-Leveling Delay Line Select
  [4:1] OSCDIV rw — Oscillator Mode Division
  [0] OSCEN rw — Oscillator Enable
0x1444 DDRPHY_DX8SL1PLLCR0 reset 0x1C0000 — DAXT8 0-1 PLL Control Register 0
  [31] PLLBYP rw — PLL Bypass
  [30] PLLRST rw — PLL Reset
  [29] PLLPD rw — PLL Power Down
  [28] RSTOPM rw — Reference Stop Mode
  [27:24] FRQSEL rw — PLL Frequency Select
  [23] RLOCKM rw — Relock Mode
  [22:17] CPPC rw — Charge Pump Proportional Current Control
  [16:13] CPIC rw — Charge Pump Integrating Current Control
  [12] GSHIFT rw — Gear Shift
  [8] ATOEN rw — Analog Test Enable (ATOEN)
  [7:4] ATC rw — Analog Test Control
  [3:0] DTC rw — Digital Test Control
0x1448 DDRPHY_DX8SL1PLLCR1 — DAXT8 0-1 PLL Control Register 1 (Type B PLL Only)
  [21:6] PLLPROG rw — Connects to the PLL PLL_PROG bus.
  [5] BYPVREGCP rw — Bypass PLL vreg_cp
  [4] BYPVREGDIG rw — Bypass PLL vreg_dig
  [3] BYPVDD rw — PLL VDD voltage level control
  [2] LOCKPS rw — Lock Detector Phase Select
  [1] LOCKCS rw — Lock Detector Counter Select
  [0] LOCKDS rw — Lock Detector Select
{0x1444+4i} DDRPHY_DX8SL1PLLCR{i} rw (i=2..4) — DAXT8 0-1 PLL Control Register {i} (Type B PLL Only)
  [31:0] PLLCTRL_{32i-33}_{32i-64} — Connectes to bits [{32i-33}:{32i-64}] of the PLL generatl control bus PLL_CTRL
0x1458 DDRPHY_DX8SL1PLLCR5 — DAXT8 0-1 PLL Control Register 5 (Type B PLL Only)
  [7:0] PLLCTRL_103_96 rw — Connectes to bits[103:96] of the PLL generatl control bus PLL_CTRL
0x145C DDRPHY_DX8SL1DQSCTL reset 0x1264000 — DATX8 0-1 DQS Control Register
  [24] RRRMODE rw — Read Path Rise-to-Rise Mode
  [21] WRRMODE rw — Write Path Rise-to-Rise Mode
  [20:19] DQSGX rw — DQS Gate Extension
  [18] LPPLLPD rw — Low Power PLL Power Down
  [17] LPIOPD rw — Low Power I/O Power Down
  [15] PDAMODE rw — Set PDA mode timing
  [14] QSCNTEN rw — QS Counter Enable
  [13] UDQIOM rw — Unused DQ I/O Mode
  [9:8] DXSR rw — Data Slew Rate
  [7:4] DQSNRES rw — DQS_N Resistor
  [3:0] DQSRES rw — DQS Resistor
0x1460 DDRPHY_DX8SL1TRNCTL ro — DATX8 0-1 Training Control Register
0x1464 DDRPHY_DX8SL1DDLCTL reset 0x2 — DATX8 0-1 DDL Control Register
  [26] DLYLDTM rw — Delay Load Timing
  [25] DXDDLLDT rw — DX DDL Load Type
  [22:18] DXDDLLD rw — DATX8 DDL Delay Select Dymainc Load
  [17:2] DXDDLBYP rw — DATX8 DDL Bypass
  [1:0] DDLBYPMODE rw — Controls DDL Bypass Mode
0x1468 DDRPHY_DX8SL1DXCTL1 reset 0x40000 — DATX8 0-1 DX Control Register 1
  [24] DXCALCLK rw — DATX Calibration Clock Select
  [23] DXRCLKMD rw — DATX8 Read Clock Mode
  [21:20] DXDTOSEL rw — DATX8 Digital Test Output Select
  [19] DXGSMD rw — Read DQS Gating Status Mode
  [18] DXQSDBYP rw — Read DQS/DQS_N Delay Load Bypass Mode
  [17] DXGDBYP rw — Read DQS Gate Delay Load Bypass Mode
  [16] DXTMODE rw — DATX8 Test Mode
0x146C DDRPHY_DX8SL1DXCTL2 reset 0x181800 — DATX8 0-1 DX Control Register 2
  [23] CRDEN rw — Configurable Read Data Enable
  [22:20] POSOEX rw — OX Extension during Post-amble
  [19:18] PREOEX rw — OE Extension during Pre-amble
  [16] IOAG rw — I/O Assisted Gate Select
  [15] IOLB rw — I/O Loopback Select
  [12:9] LPWAKEUP_THRSH rw — Low Power Wakeup Threshold
  [8] RDBI rw — Read Data Bus Inversion Enable
  [7] WDBI rw — Write Data Bus Inversion Enable
  [6] PRFBYP rw — PUB Read FIFO Bypass
  [5:4] RDMODE rw — DATX8 Receive FIFO Read Mode
  [3] DISRST rw — Disables the Read FIFO Reset
  [2:1] DQSGLB rw — Read DQS Gate I/O Loopback
0x1470 DDRPHY_DX8SL1IOCR — DATX8 0-1 I/O Configuration Register
  [30:28] DXDACRANGE rw — PVREF_DAC REFSEL range select
  [27:25] DXVREFIOM rw — IOM bits for PVREF, PVREF_DAC and PVREFE cells in DX IO ring
  [24:22] DXIOM rw — DX IO Mode
  [21:11] DXTXM rw — DX IO Transmitter Mode
  [10:0] DXRXM rw — DX IO Receiver Mode
0x1480 DDRPHY_DX8SL2OSC access not given reset 0x19FFE — DATX8 0-1 Oscillator, Delay Line Test, PHY FIFO and High Speed Reset, Loopback, and Gated Clock Control Register
  fields as DDRPHY_DX8SL1OSC
0x1484 DDRPHY_DX8SL2PLLCR0 reset 0x1C0000 — DAXT8 0-1 PLL Control Register 0
  fields as DDRPHY_DX8SL1PLLCR0
0x1488 DDRPHY_DX8SL2PLLCR1 — DAXT8 0-1 PLL Control Register 1 (Type B PLL Only)
  fields as DDRPHY_DX8SL1PLLCR1
{0x1484+4i} DDRPHY_DX8SL2PLLCR{i} rw (i=2..4) — DAXT8 0-1 PLL Control Register {i} (Type B PLL Only)
  fields as DDRPHY_DX8SL1PLLCR2
0x1498 DDRPHY_DX8SL2PLLCR5 — DAXT8 0-1 PLL Control Register 5 (Type B PLL Only)
  fields as DDRPHY_DX8SL1PLLCR5
0x149C DDRPHY_DX8SL2DQSCTL reset 0x1264000 — DATX8 0-1 DQS Control Register
  fields as DDRPHY_DX8SL1DQSCTL
0x14A0 DDRPHY_DX8SL2TRNCTL ro — DATX8 0-1 Training Control Register
0x14A4 DDRPHY_DX8SL2DDLCTL reset 0x2 — DATX8 0-1 DDL Control Register
  fields as DDRPHY_DX8SL1DDLCTL
0x14A8 DDRPHY_DX8SL2DXCTL1 reset 0x40000 — DATX8 0-1 DX Control Register 1
  fields as DDRPHY_DX8SL1DXCTL1
0x14AC DDRPHY_DX8SL2DXCTL2 reset 0x181800 — DATX8 0-1 DX Control Register 2
  fields as DDRPHY_DX8SL1DXCTL2
0x14B0 DDRPHY_DX8SL2IOCR — DATX8 0-1 I/O Configuration Register
  fields as DDRPHY_DX8SL1IOCR
0x17C0 DDRPHY_DX8SLBOSC wo — DATX8 0-8 Oscillator, Delay Line Test, PHY FIFO and High Speed Reset, Loopback, and Gated Clock Control Register
  [29:28] GATEDXRDCLK — Enable Clock Gating for DX ddr_clk
  [27:26] GATEDXDDRCLK — Enable Clock Gating for DX ctl_rd_clk
  [25:24] GATEDXCTLCLK — Enable Clock Gating for DX ctl_clk
  [23:22] CLKLEVEL — Selects the level to which clocks will be stalled when clock gating is enabled.
  [21] LBMODE — Loopback Mode
  [20] LBGSDQS — Load GSDQS LCDL with 2x the calibrated GSDQSPRD value
  [19:18] LBGDQS — Loopback DQS Gating
  [17] LBDQSS — Loopback DQS Shift
  [16] PHYHRST — PHY High-Speed Reset
  [15] PHYFRST — PHY FIFO Reset
  [14] DLTST — Delay Line Test Start
  [13] DLTMODE — Delay Line Test Mode
  [10:9] OSCWDDL — Oscillator Mode Write-Data Delay Line Select
  [6:5] OSCWDL — Oscillator Mode Write-Leveling Delay Line Select
  [4:1] OSCDIV — Oscillator Mode Division
  [0] OSCEN — Oscillator Enable
0x17C4 DDRPHY_DX8SLBPLLCR0 wo — DAXT8 0-8 PLL Control Register 0
  [31] PLLBYP — PLL Bypass
  [30] PLLRST — PLL Reset
  [29] PLLPD — PLL Power Down
  [28] RSTOPM — Reference Stop Mode
  [27:24] FRQSEL — PLL Frequency Select
  [23] RLOCKM — Relock Mode
  [22:17] CPPC — Charge Pump Proportional Current Control
  [16:13] CPIC — Charge Pump Integrating Current Control
  [12] GSHIFT — Gear Shift
  [8] ATOEN — Analog Test Enable (ATOEN)
  [7:4] ATC — Analog Test Control
  [3:0] DTC — Digital Test Control
0x17C8 DDRPHY_DX8SLBPLLCR1 wo — DAXT8 0-8 PLL Control Register 1 (Type B PLL Only)
  [21:6] PLLPROG — Connects to the PLL PLL_PROG bus.
  [5] BYPVREGCP — Bypass PLL vreg_cp
  [4] BYPVREGDIG — Bypass PLL vreg_dig
  [3] BYPVDD — PLL VDD voltage level control
  [2] LOCKPS — Lock Detector Phase Select
  [1] LOCKCS — Lock Detector Counter Select
  [0] LOCKDS — Lock Detector Select
{0x17C4+4i} DDRPHY_DX8SLBPLLCR{i} wo (i=2..4) — DAXT8 0-8 PLL Control Register {i} (Type B PLL Only)
  fields as DDRPHY_DX8SL1PLLCR2
0x17D8 DDRPHY_DX8SLBPLLCR5 wo — DAXT8 0-8 PLL Control Register 5 (Type B PLL Only)
  [7:0] PLLCTRL_103_96 — Connectes to bits[103:96] of the PLL generatl control bus PLL_CTRL
0x17DC DDRPHY_DX8SLBDQSCTL wo — DATX8 0-8 DQS Control Register
  [24] RRRMODE — Read Path Rise-to-Rise Mode
  [21] WRRMODE — Write Path Rise-to-Rise Mode
  [20:19] DQSGX — DQS Gate Extension
  [18] LPPLLPD — Low Power PLL Power Down
  [17] LPIOPD — Low Power I/O Power Down
  [15] PDAMODE — Set PDA mode timing
  [14] QSCNTEN — QS Counter Enable
  [13] UDQIOM — Unused DQ I/O Mode
  [9:8] DXSR — Data Slew Rate
  [7:4] DQSNRES — DQS# Resistor
  [3:0] DQSRES — DQS Resistor
0x17E0 DDRPHY_DX8SLBTRNCTL wo — DATX8 0-8 Training Control Register
0x17E4 DDRPHY_DX8SLBDDLCTL wo — DATX8 0-8 DDL Control Register
  [26] DLYLDTM — Delay Load Timing
  [25] DXDDLLDT — DX DDL Load Type
  [22:18] DXDDLLD — DATX8 DDL Delay Select Dymainc Load
  [17:2] DXDDLBYP — DATX8 DDL Bypass
  [1:0] DDLBYPMODE — Controls DDL Bypass Mode
0x17E8 DDRPHY_DX8SLBDXCTL1 wo — DATX8 0-8 DX Control Register 1
  [24] DXCALCLK — DATX Calibration Clock Select
  [23] DXRCLKMD — DATX8 Read Clock Mode
  [21:20] DXDTOSEL — DATX8 Digital Test Output Select
  [19] DXGSMD — Read DQS Gating Status Mode
  [18] DXQSDBYP — Read DQS/DQS# Delay Load Bypass Mode
  [17] DXGDBYP — Read DQS Gate Delay Load Bypass Mode
  [16] DXTMODE — DATX8 Test Mode
0x17EC DDRPHY_DX8SLBDXCTL2 wo — DATX8 0-8 DX Control Register 2
  [23] CRDEN — Configurable Read Data Enable
  [22:20] POSOEX — OX Extension during Post-amble
  [19:18] PREOEX — OE Extension during Pre-amble
  [16] IOAG — I/O Assisted Gate Select
  [15] IOLB — I/O Loopback Select
  [12:9] LPWAKEUP_THRSH — Low Power Wakeup Threshold
  [8] RDBI — Read Data Bus Inversion Enable
  [7] WDBI — Write Data Bus Inversion Enable
  [6] PRFBYP — PUB Read FIFO Bypass
  [5:4] RDMODE — DATX8 Receive FIFO Read Mode
  [3] DISRST — Disables the Read FIFO Reset
  [2:1] DQSGLB — Read DQS Gate I/O Loopback
0x17F0 DDRPHY_DX8SLBIOCR wo — DATX8 0-8 I/O Configuration Register
  [30:28] DXDACRANGE — PVREF_DAC REFSEL range select
  [27:25] DXVREFIOM — IOM bits for PVREF, PVREF_DAC and PVREFE cells in DX IO ring
  [24:22] DXIOM — DX IO Mode
  [21:11] DXTXM — DX IO Transmitter Mode
  [10:0] DXRXM — DX IO Receiver Mode
0x17F4 DDRPHY_DX4SLBIOCR wo — DATX4 0-8 I/O Configuration Register
